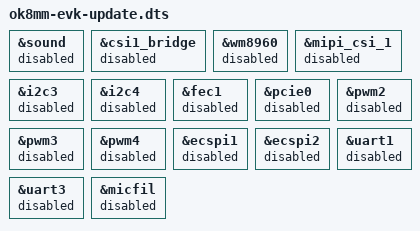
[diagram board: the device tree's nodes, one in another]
/*
 * Copyright 2018 NXP
 *
 * This program is free software; you can redistribute it and/or
 * modify it under the terms of the GNU General Public License
 * as published by the Free Software Foundation; either version 2
 * of the License, or (at your option) any later version.
 *
 * This program is distributed in the hope that it will be useful,
 * but WITHOUT ANY WARRANTY; without even the implied warranty of
 * MERCHANTABILITY or FITNESS FOR A PARTICULAR PURPOSE.  See the
 * GNU General Public License for more details.
 */

#include "ok8mm-evk.dts"
&sound {
	status = "disabled";
};

&csi1_bridge {
	status = "disabled";
};

&wm8960 {
	status = "disabled";
};

&mipi_csi_1 {
	status = "disabled";
};

&i2c3 {
	status = "disabled";
};

&i2c4{
	status = "disabled";
};

&fec1 {
	status = "disabled";
};

&pcie0{
	status = "disabled";
};

&pwm2 {
	status = "disabled";
};

&pwm3 {
	status = "disabled";
};

&pwm4 {
	status = "disabled";
};

&ecspi1 {
	status = "disabled";
};

&ecspi2 {
	status = "disabled";
};

&uart1 {
	status = "disabled";
};

&uart3 {
	status = "disabled";
};

&micfil {
	status = "disabled";
};
